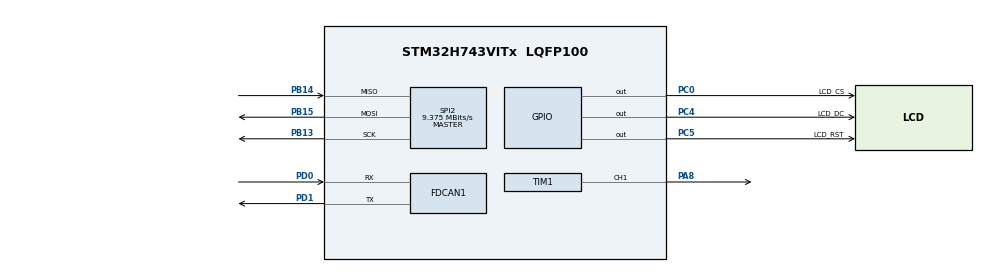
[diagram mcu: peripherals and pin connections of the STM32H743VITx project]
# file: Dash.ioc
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CORTEX_M7.default_mode_Activation=1
FDCAN1.CalculateBaudRateNominal=500000
FDCAN1.CalculateTimeBitNominal=2000
FDCAN1.CalculateTimeQuantumNominal=80.0
FDCAN1.NominalPrescaler=2
FDCAN1.NominalTimeSeg1=19
FDCAN1.NominalTimeSeg2=5
FDCAN1.RxFifo0ElmtsNbr=16
FDCAN1.StdFiltersNbr=4
FDCAN1.TxFifoQueueElmtsNbr=32
FREERTOS.Tasks01=defaultTask,24,4096,StartDefaultTask,Default,NULL,Dynamic,NULL,NULL
FREERTOS.configTOTAL_HEAP_SIZE=65536
FREERTOS.configUSE_NEWLIB_REENTRANT=1
Mcu.Family=STM32H7
Mcu.Name=STM32H743VITx
Mcu.Package=LQFP100
NVIC.PriorityGroup=NVIC_PRIORITYGROUP_4
NVIC.TIM6_DAC_IRQn=true\:15\:0\:false\:false\:true\:false\:false\:true\:true
NVIC.TimeBase=TIM6_DAC_IRQn
NVIC.TimeBaseIP=TIM6
PA8.Signal=S_TIM1_CH1
PB13.Mode=Full_Duplex_Master
PB13.Signal=SPI2_SCK
PC0.GPIO_Label=LCD_CS
PC0.Signal=GPIO_Output
PB15.Mode=Full_Duplex_Master
PB15.Signal=SPI2_MOSI
PB14.Mode=Full_Duplex_Master
PB14.Signal=SPI2_MISO
PC4.GPIO_Label=LCD_DC
PC4.Signal=GPIO_Output
PC5.GPIO_Label=LCD_RST
PC5.Signal=GPIO_Output
PD0.Mode=FDCAN_Activate
PD0.Signal=FDCAN1_RX
PD1.Mode=FDCAN_Activate
PD1.Signal=FDCAN1_TX
PH0-OSC_IN\ (PH0).Mode=HSE-External-Oscillator
PH0-OSC_IN\ (PH0).Signal=RCC_OSC_IN
PH1-OSC_OUT\ (PH1).Mode=HSE-External-Oscillator
PH1-OSC_OUT\ (PH1).Signal=RCC_OSC_OUT
ProjectManager.HeapSize=0x200
ProjectManager.StackSize=0x400
ProjectManager.TargetToolchain=STM32CubeIDE
RCC.ADCFreq_Value=129000000
RCC.APB1Freq_Value=112500000
RCC.APB2Freq_Value=112500000
RCC.APB3Freq_Value=112500000
RCC.APB4Freq_Value=112500000
RCC.CortexFreq_Value=225000000
RCC.D1PPRE=RCC_APB3_DIV2
RCC.D2PPRE1=RCC_APB1_DIV2
RCC.D2PPRE2=RCC_APB2_DIV2
RCC.D3PPRE=RCC_APB4_DIV2
RCC.DIVM1=4
RCC.DIVN1=28
RCC.DIVQ1=3
RCC.FDCANCLockSelection=RCC_FDCANCLKSOURCE_HSE
RCC.HCLKFreq_Value=225000000
RCC.PLLFRACN=1024
RCC.SYSCLKFreq_VALUE=225000000
RCC.SYSCLKSource=RCC_SYSCLKSOURCE_PLLCLK
RCC.USBFreq_Value=150000000
SH.S_TIM1_CH1.0=TIM1_CH1,PWM Generation1 CH1
SPI2.BaudRatePrescaler=SPI_BAUDRATEPRESCALER_16
SPI2.CLKPhase=SPI_PHASE_1EDGE
SPI2.CLKPolarity=SPI_POLARITY_LOW
SPI2.CalculateBaudRate=9.375 MBits/s
SPI2.DataSize=SPI_DATASIZE_8BIT
SPI2.Direction=SPI_DIRECTION_2LINES
SPI2.Mode=SPI_MODE_MASTER
SPI2.VirtualType=VM_MASTER
TIM1.Channel-PWM\ Generation1\ CH1=TIM_CHANNEL_1
TIM1.Period=999
TIM1.Prescaler=239
VP_FREERTOS_VS_CMSIS_V2.Mode=CMSIS_V2
VP_MEMORYMAP_VS_MEMORYMAP.Mode=CurAppReg
VP_SYS_VS_tim6.Mode=TIM6
board=custom

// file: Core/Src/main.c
/* USER CODE BEGIN Header */
/**
  ******************************************************************************
  * @file           : main.c
  * @brief          : Main program body
  ******************************************************************************
  * @attention
  *
  * Copyright (c) 2026 STMicroelectronics.
  * All rights reserved.
  *
  * This software is licensed under terms that can be found in the LICENSE file
  * in the root directory of this software component.
  * If no LICENSE file comes with this software, it is provided AS-IS.
  *
  ******************************************************************************
  */
/* USER CODE END Header */
#include "main.h"
#include "FreeRTOS.h"
#include "cmsis_os2.h"
#include "fdcan.h"
#include "spi.h"
#include "tim.h"
#include "gpio.h"

/* USER CODE BEGIN Includes */
#include "fault.h"
/* USER CODE END Includes */

void SystemClock_Config(void);
static void MPU_Config(void);
void MX_FREERTOS_Init(void);

int main(void)
{

  /* MPU Configuration--------------------------------------------------------*/
  MPU_Config();

  /* MCU Configuration--------------------------------------------------------*/

  /* Reset of all peripherals, Initializes the Flash interface and the Systick. */
  HAL_Init();

  /* USER CODE BEGIN Init */
  /* As early as the HAL tick runs (HAL_Init started the TIM6 timebase): latch
   * the reset cause, then start the watchdog with its long boot timeout, so a
   * hang in SystemClock_Config (its VOSRDY / PLL waits), peripheral init, RTOS
   * start or the display bring-up also ends in a reset. The IWDG runs from the
   * LSI, independent of the clock tree being reconfigured. AppMain_Init
   * switches it to the run timeout. */
  fault_init();
  fault_wdg_start_boot();

  /* Caches (CubeMX leaves both off in Dash.ioc; enabled here so regeneration
   * keeps them). Code runs from flash and all data/bss/stack sit in AXI SRAM,
   * so both matter for LVGL rendering. Coherency: the only DMA in the project
   * is the display flush, which cleans its buffer before each transfer
   * (lv_port_disp.c); the fault record is in DTCM, which is never cached, so
   * it still survives a reset; FDCAN message RAM is device memory. Any new DMA
   * must clean/invalidate its buffers or use a non-cacheable MPU region. */
  SCB_EnableICache();
  SCB_EnableDCache();
  /* USER CODE END Init */

  /* Configure the system clock */
  SystemClock_Config();

  /* Initialize all configured peripherals */
  MX_GPIO_Init();
  MX_FDCAN1_Init();
  MX_SPI2_Init();
  MX_TIM1_Init();

  /* Init scheduler */
  osKernelInitialize();  /* Call init function for freertos objects (in cmsis_os2.c) */
  MX_FREERTOS_Init();

  /* Start scheduler */
  osKernelStart();

  /* We should never get here as control is now taken by the scheduler */

  /* Infinite loop */
  while (1)
  {

  }
}

void SystemClock_Config(void)
{
  RCC_OscInitTypeDef RCC_OscInitStruct = {0};
  RCC_ClkInitTypeDef RCC_ClkInitStruct = {0};

  /** Supply configuration update enable
  */
  HAL_PWREx_ConfigSupply(PWR_LDO_SUPPLY);

  /** Configure the main internal regulator output voltage
  */
  __HAL_PWR_VOLTAGESCALING_CONFIG(PWR_REGULATOR_VOLTAGE_SCALE1);

  while(!__HAL_PWR_GET_FLAG(PWR_FLAG_VOSRDY)) {}

  /** Initializes the RCC Oscillators according to the specified parameters
  * in the RCC_OscInitTypeDef structure.
  */
  RCC_OscInitStruct.OscillatorType = RCC_OSCILLATORTYPE_HSI|RCC_OSCILLATORTYPE_HSE;
  RCC_OscInitStruct.HSEState = RCC_HSE_ON;
  RCC_OscInitStruct.HSIState = RCC_HSI_DIV1;
  RCC_OscInitStruct.HSICalibrationValue = RCC_HSICALIBRATION_DEFAULT;
  RCC_OscInitStruct.PLL.PLLState = RCC_PLL_ON;
  RCC_OscInitStruct.PLL.PLLSource = RCC_PLLSOURCE_HSI;
  RCC_OscInitStruct.PLL.PLLM = 4;
  RCC_OscInitStruct.PLL.PLLN = 28;
  RCC_OscInitStruct.PLL.PLLP = 2;
  RCC_OscInitStruct.PLL.PLLQ = 3;
  RCC_OscInitStruct.PLL.PLLR = 2;
  RCC_OscInitStruct.PLL.PLLRGE = RCC_PLL1VCIRANGE_3;
  RCC_OscInitStruct.PLL.PLLVCOSEL = RCC_PLL1VCOWIDE;
  RCC_OscInitStruct.PLL.PLLFRACN = 1024;
  if (HAL_RCC_OscConfig(&RCC_OscInitStruct) != HAL_OK)
  {
    Error_Handler();
  }

  /** Initializes the CPU, AHB and APB buses clocks
  */
  RCC_ClkInitStruct.ClockType = RCC_CLOCKTYPE_HCLK|RCC_CLOCKTYPE_SYSCLK
                              |RCC_CLOCKTYPE_PCLK1|RCC_CLOCKTYPE_PCLK2
                              |RCC_CLOCKTYPE_D3PCLK1|RCC_CLOCKTYPE_D1PCLK1;
  RCC_ClkInitStruct.SYSCLKSource = RCC_SYSCLKSOURCE_PLLCLK;
  RCC_ClkInitStruct.SYSCLKDivider = RCC_SYSCLK_DIV1;
  RCC_ClkInitStruct.AHBCLKDivider = RCC_HCLK_DIV1;
  RCC_ClkInitStruct.APB3CLKDivider = RCC_APB3_DIV2;
  RCC_ClkInitStruct.APB1CLKDivider = RCC_APB1_DIV2;
  RCC_ClkInitStruct.APB2CLKDivider = RCC_APB2_DIV2;
  RCC_ClkInitStruct.APB4CLKDivider = RCC_APB4_DIV2;

  if (HAL_RCC_ClockConfig(&RCC_ClkInitStruct, FLASH_LATENCY_4) != HAL_OK)
  {
    Error_Handler();
  }
}

 /* MPU Configuration */

void MPU_Config(void)
{
  MPU_Region_InitTypeDef MPU_InitStruct = {0};

  /* Disables the MPU */
  HAL_MPU_Disable();

  /** Initializes and configures the Region and the memory to be protected
  */
  MPU_InitStruct.Enable = MPU_REGION_ENABLE;
  MPU_InitStruct.Number = MPU_REGION_NUMBER0;
  MPU_InitStruct.BaseAddress = 0x0;
  MPU_InitStruct.Size = MPU_REGION_SIZE_4GB;
  MPU_InitStruct.SubRegionDisable = 0x87;
  MPU_InitStruct.TypeExtField = MPU_TEX_LEVEL0;
  MPU_InitStruct.AccessPermission = MPU_REGION_NO_ACCESS;
  MPU_InitStruct.DisableExec = MPU_INSTRUCTION_ACCESS_DISABLE;
  MPU_InitStruct.IsShareable = MPU_ACCESS_SHAREABLE;
  MPU_InitStruct.IsCacheable = MPU_ACCESS_NOT_CACHEABLE;
  MPU_InitStruct.IsBufferable = MPU_ACCESS_NOT_BUFFERABLE;

  HAL_MPU_ConfigRegion(&MPU_InitStruct);
  /* Enables the MPU */
  HAL_MPU_Enable(MPU_PRIVILEGED_DEFAULT);

}

void HAL_TIM_PeriodElapsedCallback(TIM_HandleTypeDef *htim)
{
  if (htim->Instance == TIM6)
  {
    HAL_IncTick();
  }
}

void Error_Handler(void)
{
  /* USER CODE BEGIN Error_Handler_Debug */
  /* User can add his own implementation to report the HAL error return state */
  /* Recorded for the next boot. The IWDG runs from right after HAL_Init
   * (~10 s boot timeout), so this stop always ends in a watchdog reset —
   * also in clock / peripheral init. A fault that repeats there (e.g. HSE
   * not starting: FDCAN needs it) is a silent reset loop with the heartbeat
   * LED off and no panel; DIAG shows "LAST RESET: HAL ERROR xN" only once a
   * boot gets that far. */
  fault_record(FAULT_ERROR_HANDLER);
  __disable_irq();
  while (1)
  {
  }
  /* USER CODE END Error_Handler_Debug */
}

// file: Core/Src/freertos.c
/* USER CODE BEGIN Header */
/**
  ******************************************************************************
  * File Name          : freertos.c
  * Description        : Code for freertos applications
  ******************************************************************************
  * @attention
  *
  * Copyright (c) 2026 STMicroelectronics.
  * All rights reserved.
  *
  * This software is licensed under terms that can be found in the LICENSE file
  * in the root directory of this software component.
  * If no LICENSE file comes with this software, it is provided AS-IS.
  *
  ******************************************************************************
  */
/* USER CODE END Header */

#include "FreeRTOS.h"
#include "task.h"
#include "main.h"
#include "FreeRTOS.h"
#include "cmsis_os2.h"

/* USER CODE BEGIN Includes */
#include "app_main.h"
#include "fault.h"
/* USER CODE END Includes */

/* Definitions for defaultTask */
osThreadId_t defaultTaskHandle;
const osThreadAttr_t defaultTask_attributes = {
  .name = "defaultTask",
  .stack_size = 1024 * 16,   /* 16 KB: LVGL rendering of the rich cluster (arc + masks
                              * + ~120 nested objects) overflows the old 4 KB stack,
                              * which silently froze the loop. RAM_D1 has plenty. */
  .priority = (osPriority_t) osPriorityNormal,
};

void StartDefaultTask(void *argument);

void MX_FREERTOS_Init(void); /* (MISRA C 2004 rule 8.1) */

void MX_FREERTOS_Init(void) {

  /* Create the thread(s) */
  /* creation of defaultTask */
  defaultTaskHandle = osThreadNew(StartDefaultTask, NULL, &defaultTask_attributes);

  /* USER CODE BEGIN RTOS_THREADS */
  /* No task (FreeRTOS heap too small for its 16 KB stack): nothing would ever
   * run but the idle task. Record why and stop; the boot IWDG resets the
   * board (review C7 SW-07). The DIAG page lives in this very task, so the
   * code is for a debugger (s_rec in .noinit) rather than the screen. */
  if (defaultTaskHandle == NULL) {
    fault_record(FAULT_RTOS_INIT);
    __disable_irq();
    for (;;) { }
  }
  /* USER CODE END RTOS_THREADS */

}

void StartDefaultTask(void *argument)
{
  /* USER CODE BEGIN StartDefaultTask */
  AppMain_Init();

  /* Infinite loop */
  for(;;)
  {
    AppMain_Run();
    osDelay(5);
  }
  /* USER CODE END StartDefaultTask */
}
